VERSION ""

NS_ :

BS_:

BU_: XXX

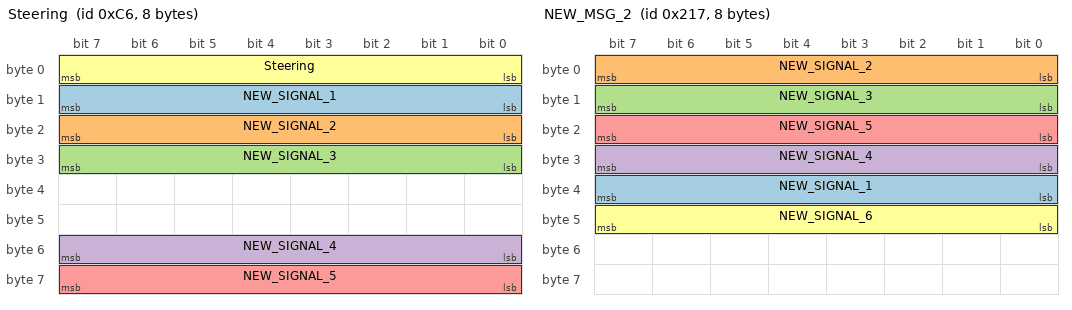
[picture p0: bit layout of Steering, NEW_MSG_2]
BO_ 198 Steering: 8 XXX
 SG_ NEW_SIGNAL_1 : 15|8@0+ (1,0) [0|255] "" XXX
 SG_ NEW_SIGNAL_2 : 23|8@0+ (1,0) [0|255] "" XXX
 SG_ NEW_SIGNAL_3 : 31|8@0+ (1,0) [0|255] "" XXX
 SG_ NEW_SIGNAL_4 : 55|8@0+ (1,0) [0|255] "" XXX
 SG_ NEW_SIGNAL_5 : 63|8@0+ (1,0) [0|255] "" XXX
 SG_ Steering : 7|8@0+ (1,0) [0|255] "" XXX

BO_ 535 NEW_MSG_2: 8 XXX
 SG_ NEW_SIGNAL_1 : 39|8@0+ (1,0) [0|255] "" XXX
 SG_ NEW_SIGNAL_2 : 7|8@0+ (1,0) [0|255] "" XXX
 SG_ NEW_SIGNAL_3 : 15|8@0+ (1,0) [0|255] "" XXX
 SG_ NEW_SIGNAL_4 : 31|8@0+ (1,0) [0|255] "" XXX
 SG_ NEW_SIGNAL_5 : 23|8@0+ (1,0) [0|255] "" XXX
 SG_ NEW_SIGNAL_6 : 47|8@0+ (1,0) [0|255] "" XXX

BO_ 1642 NEW_MSG_3: 8 XXX
 SG_ NEW_SIGNAL_1 : 31|8@0+ (1,0) [0|255] "" XXX
 SG_ NEW_SIGNAL_2 : 39|8@0+ (1,0) [0|255] "" XXX

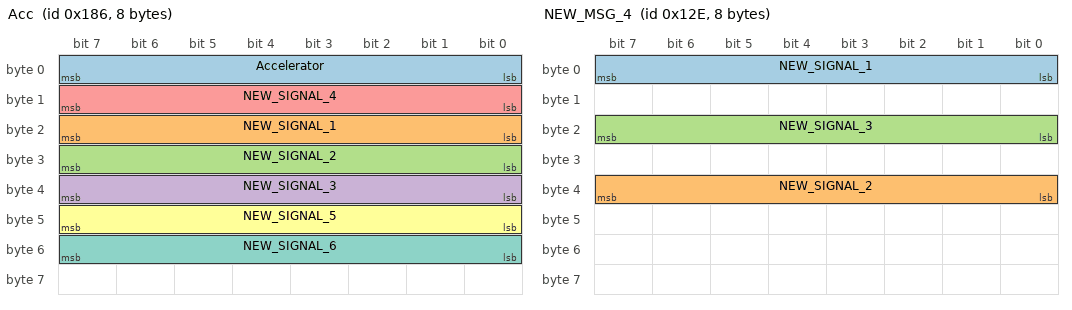
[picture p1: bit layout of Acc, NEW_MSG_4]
BO_ 390 Acc: 8 XXX
 SG_ Accelerator : 7|8@0+ (1,0) [0|255] "" XXX
 SG_ NEW_SIGNAL_1 : 23|8@0+ (1,0) [0|255] "" XXX
 SG_ NEW_SIGNAL_2 : 31|8@0+ (1,0) [0|255] "" XXX
 SG_ NEW_SIGNAL_3 : 39|8@0+ (1,0) [0|255] "" XXX
 SG_ NEW_SIGNAL_4 : 15|8@0+ (1,0) [0|255] "" XXX
 SG_ NEW_SIGNAL_5 : 47|8@0+ (1,0) [0|255] "" XXX
 SG_ NEW_SIGNAL_6 : 55|8@0+ (1,0) [0|255] "" XXX

BO_ 302 NEW_MSG_4: 8 XXX
 SG_ NEW_SIGNAL_1 : 7|8@0+ (1,0) [0|255] "" XXX
 SG_ NEW_SIGNAL_2 : 39|8@0+ (1,0) [0|255] "" XXX
 SG_ NEW_SIGNAL_3 : 23|8@0+ (1,0) [0|255] "" XXX

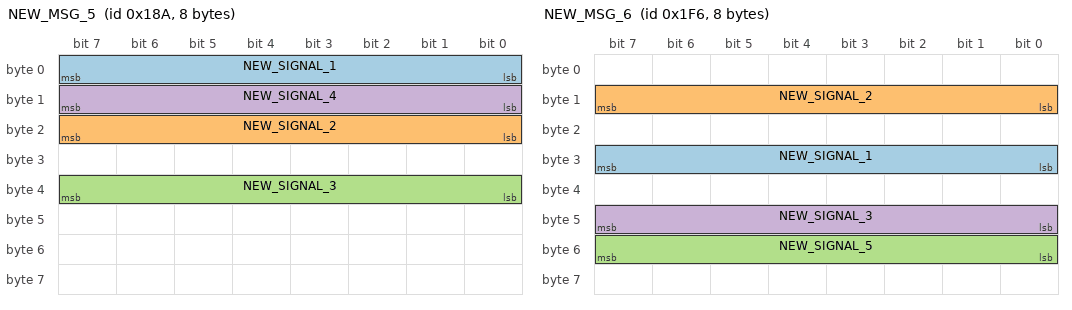
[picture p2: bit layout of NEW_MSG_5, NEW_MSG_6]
BO_ 394 NEW_MSG_5: 8 XXX
 SG_ NEW_SIGNAL_1 : 7|8@0+ (1,0) [0|255] "" XXX
 SG_ NEW_SIGNAL_2 : 23|8@0+ (1,0) [0|255] "" XXX
 SG_ NEW_SIGNAL_3 : 39|8@0+ (1,0) [0|255] "" XXX
 SG_ NEW_SIGNAL_4 : 15|8@0+ (1,0) [0|255] "" XXX

BO_ 502 NEW_MSG_6: 8 XXX
 SG_ NEW_SIGNAL_1 : 31|8@0+ (1,0) [0|255] "" XXX
 SG_ NEW_SIGNAL_2 : 15|8@0+ (1,0) [0|255] "" XXX
 SG_ NEW_SIGNAL_5 : 55|8@0+ (1,0) [0|255] "" XXX
 SG_ NEW_SIGNAL_3 : 47|8@0+ (1,0) [0|255] "" XXX

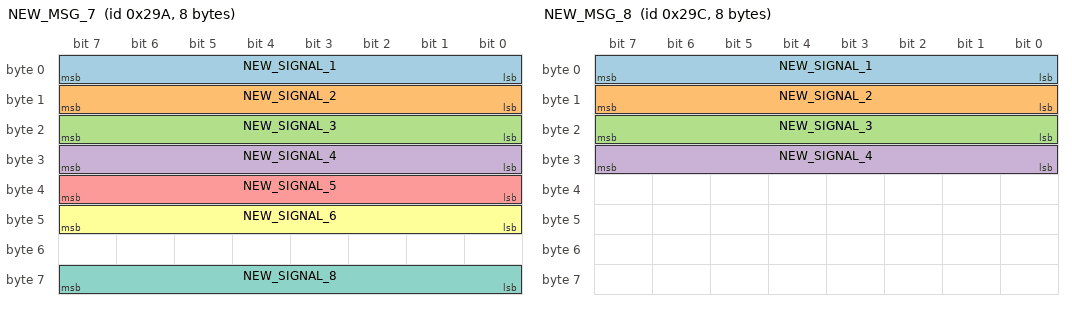
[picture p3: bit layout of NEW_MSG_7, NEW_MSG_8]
BO_ 666 NEW_MSG_7: 8 XXX
 SG_ NEW_SIGNAL_1 : 7|8@0+ (1,0) [0|255] "" XXX
 SG_ NEW_SIGNAL_2 : 15|8@0+ (1,0) [0|255] "" XXX
 SG_ NEW_SIGNAL_3 : 23|8@0+ (1,0) [0|255] "" XXX
 SG_ NEW_SIGNAL_4 : 31|8@0+ (1,0) [0|255] "" XXX
 SG_ NEW_SIGNAL_5 : 39|8@0+ (1,0) [0|255] "" XXX
 SG_ NEW_SIGNAL_6 : 47|8@0+ (1,0) [0|255] "" XXX
 SG_ NEW_SIGNAL_8 : 63|8@0+ (1,0) [0|255] "" XXX

BO_ 668 NEW_MSG_8: 8 XXX
 SG_ NEW_SIGNAL_1 : 7|8@0+ (1,0) [0|255] "" XXX
 SG_ NEW_SIGNAL_2 : 15|8@0+ (1,0) [0|255] "" XXX
 SG_ NEW_SIGNAL_3 : 23|8@0+ (1,0) [0|255] "" XXX
 SG_ NEW_SIGNAL_4 : 31|8@0+ (1,0) [0|255] "" XXX

BO_ 529 NEW_MSG_9: 8 XXX
 SG_ NEW_SIGNAL_1 : 15|8@0+ (1,0) [0|255] "" XXX
 SG_ NEW_SIGNAL_3 : 31|8@0+ (1,0) [0|255] "" XXX

BO_ 850 Brake: 8 XXX
 SG_ Brake : 31|8@0+ (1,0) [0|255] "" XXX

BO_ 852 NEW_MSG_10: 8 XXX
 SG_ NEW_SIGNAL_1 : 7|8@0+ (1,0) [0|255] "" XXX
 SG_ NEW_SIGNAL_2 : 15|8@0+ (1,0) [0|255] "" XXX

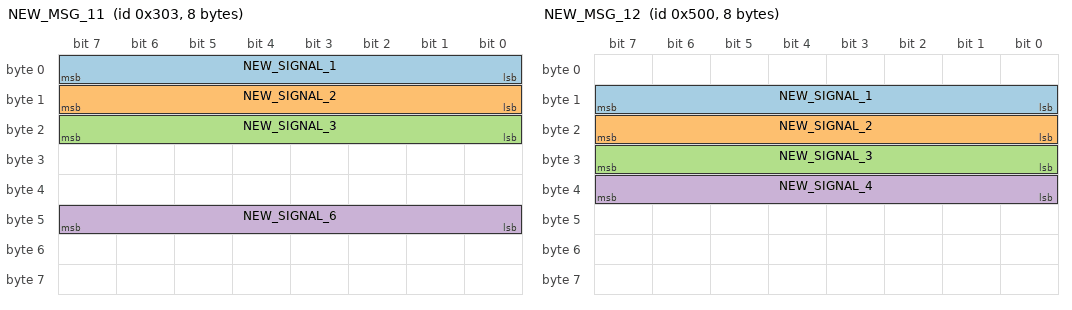
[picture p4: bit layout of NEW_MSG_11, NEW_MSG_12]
BO_ 771 NEW_MSG_11: 8 XXX
 SG_ NEW_SIGNAL_1 : 7|8@0+ (1,0) [0|255] "" XXX
 SG_ NEW_SIGNAL_2 : 15|8@0+ (1,0) [0|255] "" XXX
 SG_ NEW_SIGNAL_3 : 23|8@0+ (1,0) [0|255] "" XXX
 SG_ NEW_SIGNAL_6 : 47|8@0+ (1,0) [0|255] "" XXX

BO_ 1280 NEW_MSG_12: 8 XXX
 SG_ NEW_SIGNAL_1 : 15|8@0+ (1,0) [0|255] "" XXX
 SG_ NEW_SIGNAL_2 : 23|8@0+ (1,0) [0|255] "" XXX
 SG_ NEW_SIGNAL_3 : 31|8@0+ (1,0) [0|255] "" XXX
 SG_ NEW_SIGNAL_4 : 39|8@0+ (1,0) [0|255] "" XXX

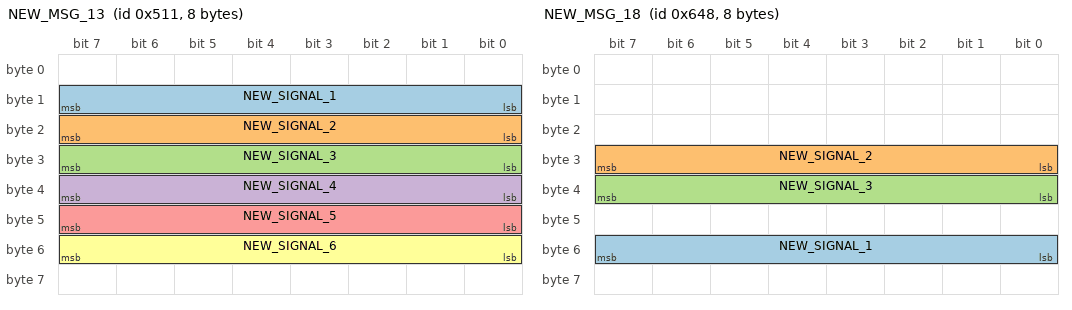
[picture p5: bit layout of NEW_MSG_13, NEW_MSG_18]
BO_ 1297 NEW_MSG_13: 8 XXX
 SG_ NEW_SIGNAL_1 : 15|8@0+ (1,0) [0|255] "" XXX
 SG_ NEW_SIGNAL_2 : 23|8@0+ (1,0) [0|255] "" XXX
 SG_ NEW_SIGNAL_3 : 31|8@0+ (1,0) [0|255] "" XXX
 SG_ NEW_SIGNAL_4 : 39|8@0+ (1,0) [0|255] "" XXX
 SG_ NEW_SIGNAL_5 : 47|8@0+ (1,0) [0|255] "" XXX
 SG_ NEW_SIGNAL_6 : 55|8@0+ (1,0) [0|255] "" XXX

BO_ 1379 NEW_MSG_14: 8 XXX
 SG_ NEW_SIGNAL_1 : 7|8@0+ (1,0) [0|255] "" XXX
 SG_ NEW_SIGNAL_2 : 15|8@0+ (1,0) [0|255] "" XXX

BO_ 1380 NEW_MSG_15: 8 XXX
 SG_ NEW_SIGNAL_1 : 7|8@0+ (1,0) [0|255] "" XXX
 SG_ NEW_SIGNAL_2 : 15|8@0+ (1,0) [0|255] "" XXX

BO_ 1495 NEW_MSG_16: 8 XXX
 SG_ NEW_SIGNAL_1 : 7|8@0+ (1,0) [0|255] "" XXX
 SG_ NEW_SIGNAL_2 : 15|8@0+ (1,0) [0|255] "" XXX

BO_ 1628 NEW_MSG_17: 8 XXX
 SG_ NEW_SIGNAL_1 : 15|8@0+ (1,0) [0|255] "" XXX

BO_ 1608 NEW_MSG_18: 8 XXX
 SG_ NEW_SIGNAL_1 : 55|8@0+ (1,0) [0|255] "" XXX
 SG_ NEW_SIGNAL_2 : 31|8@0+ (1,0) [0|255] "" XXX
 SG_ NEW_SIGNAL_3 : 39|8@0+ (1,0) [0|255] "" XXX

BO_ 848 NEW_MSG_1: 8 XXX
 SG_ NEW_SIGNAL_1 : 47|8@0+ (1,0) [0|255] "" XXX

BO_ 1373 NEW_MSG_19: 8 XXX
 SG_ NEW_SIGNAL_1 : 23|8@0+ (1,0) [0|255] "" XXX
 SG_ NEW_SIGNAL_2 : 15|8@0+ (1,0) [0|255] "" XXX

BO_ 1502 NEW_MSG_20: 8 XXX
 SG_ NEW_SIGNAL_1 : 7|8@0+ (1,0) [0|255] "" XXX

BO_ 1498 NEW_MSG_21: 8 XXX
 SG_ NEW_SIGNAL_1 : 7|8@0+ (1,0) [0|255] "" XXX
